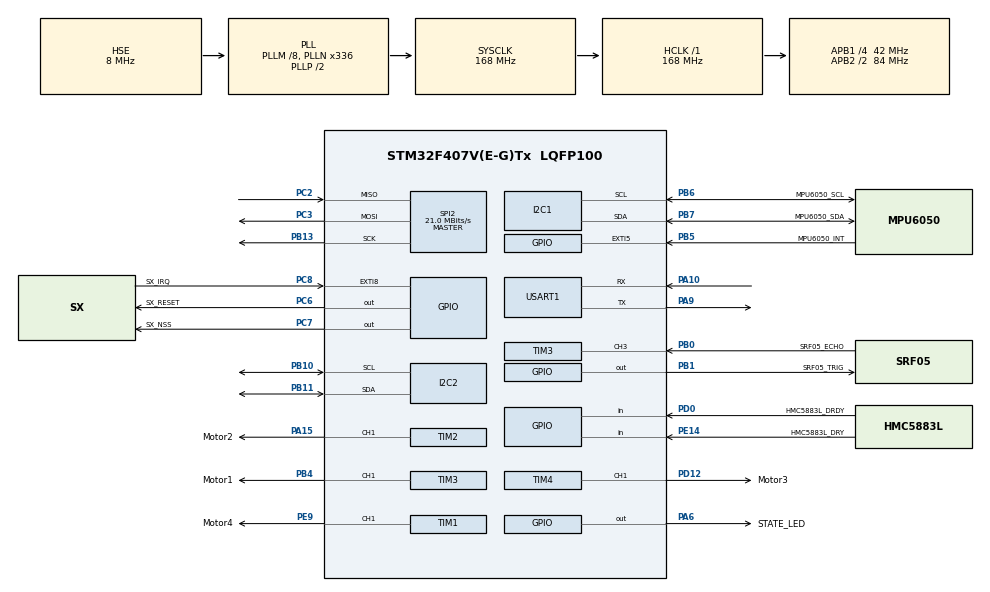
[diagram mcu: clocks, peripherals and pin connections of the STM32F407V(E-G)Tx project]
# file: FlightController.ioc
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Mcu.Family=STM32F4
Mcu.Name=STM32F407V(E-G)Tx
Mcu.Package=LQFP100
NVIC.EXTI9_5_IRQn=true\:0\:0\:false\:false\:true\:true\:true\:true
NVIC.PriorityGroup=NVIC_PRIORITYGROUP_4
NVIC.TIM3_IRQn=true\:0\:0\:false\:false\:true\:true\:true\:true
NVIC.USART1_IRQn=true\:0\:0\:false\:false\:true\:true\:true\:true
PA10.GPIO_PuPd=GPIO_PULLUP
PA10.Mode=Asynchronous
PA10.Signal=USART1_RX
PA13.Mode=Serial_Wire
PA13.Signal=SYS_JTMS-SWDIO
PA14.Mode=Serial_Wire
PA14.Signal=SYS_JTCK-SWCLK
PA15.GPIO_Label=Motor2
PA15.Signal=S_TIM2_CH1_ETR
PA6.GPIO_Label=STATE_LED
PA6.GPIO_PuPd=GPIO_NOPULL
PA6.PinState=GPIO_PIN_SET
PA6.Signal=GPIO_Output
PA9.Mode=Asynchronous
PA9.Signal=USART1_TX
PB0.GPIO_Label=SRF05_ECHO
PB0.Signal=S_TIM3_CH3
PB1.GPIO_Label=SRF05_TRIG
PB1.Signal=GPIO_Output
PB10.Mode=I2C
PB10.Signal=I2C2_SCL
PB11.Mode=I2C
PB11.Signal=I2C2_SDA
PB13.GPIO_Mode=GPIO_MODE_AF_PP
PB13.GPIO_PuPd=GPIO_NOPULL
PB13.GPIO_Speed=GPIO_SPEED_FREQ_VERY_HIGH
PB13.Mode=Full_Duplex_Master
PB13.Signal=SPI2_SCK
PB4.GPIO_Label=Motor1
PB4.Signal=S_TIM3_CH1
PB5.GPIO_Label=MPU6050_INT
PB5.Signal=GPXTI5
PB6.GPIO_Label=MPU6050_SCL
PB6.Mode=I2C
PB6.Signal=I2C1_SCL
PB7.GPIO_Label=MPU6050_SDA
PB7.Mode=I2C
PB7.Signal=I2C1_SDA
PC2.GPIO_Mode=GPIO_MODE_AF_PP
PC2.GPIO_PuPd=GPIO_NOPULL
PC2.GPIO_Speed=GPIO_SPEED_FREQ_VERY_HIGH
PC2.Mode=Full_Duplex_Master
PC2.Signal=SPI2_MISO
PC3.GPIO_Mode=GPIO_MODE_AF_PP
PC3.GPIO_PuPd=GPIO_NOPULL
PC3.GPIO_Speed=GPIO_SPEED_FREQ_VERY_HIGH
PC3.Mode=Full_Duplex_Master
PC3.Signal=SPI2_MOSI
PC6.GPIO_Label=SX_RESET
PC6.PinState=GPIO_PIN_RESET
PC6.Signal=GPIO_Output
PC7.GPIO_Label=SX_NSS
PC7.PinState=GPIO_PIN_SET
PC7.Signal=GPIO_Output
PC8.GPIO_Label=SX_IRQ
PC8.Signal=GPXTI8
PD0.GPIO_Label=HMC5883L_DRDY
PD0.Signal=GPIO_Input
PD12.GPIO_Label=Motor3
PD12.Signal=S_TIM4_CH1
PE14.GPIO_Label=HMC5883L_DRY
PE14.Signal=GPIO_Input
PE9.GPIO_Label=Motor4
PE9.Signal=S_TIM1_CH1
PH0-OSC_IN.Mode=HSE-External-Oscillator
PH0-OSC_IN.Signal=RCC_OSC_IN
PH1-OSC_OUT.Mode=HSE-External-Oscillator
PH1-OSC_OUT.Signal=RCC_OSC_OUT
ProjectManager.HeapSize=0x200
ProjectManager.StackSize=0x400
ProjectManager.TargetToolchain=CMake
RCC.48MHZClocksFreq_Value=84000000
RCC.AHBFreq_Value=168000000
RCC.APB1CLKDivider=RCC_HCLK_DIV4
RCC.APB1Freq_Value=42000000
RCC.APB1TimFreq_Value=84000000
RCC.APB2CLKDivider=RCC_HCLK_DIV2
RCC.APB2Freq_Value=84000000
RCC.APB2TimFreq_Value=168000000
RCC.CortexFreq_Value=168000000
RCC.HCLKFreq_Value=168000000
RCC.HSE_VALUE=8000000
RCC.HSI_VALUE=16000000
RCC.LSE_VALUE=32768
RCC.PLLM=8
RCC.PLLN=336
RCC.PLLSourceVirtual=RCC_PLLSOURCE_HSE
RCC.SYSCLKFreq_VALUE=168000000
RCC.SYSCLKSource=RCC_SYSCLKSOURCE_PLLCLK
RCC.VCOOutputFreq_Value=336000000
SH.S_TIM1_CH1.0=TIM1_CH1,PWM Generation1 CH1
SH.S_TIM2_CH1_ETR.0=TIM2_CH1,PWM Generation1 CH1
SH.S_TIM3_CH1.0=TIM3_CH1,PWM Generation1 CH1
SH.S_TIM3_CH3.0=TIM3_CH3,Input_Capture3_from_TI3
SH.S_TIM4_CH1.0=TIM4_CH1,PWM Generation1 CH1
SPI2.BaudRatePrescaler=SPI_BAUDRATEPRESCALER_2
SPI2.CalculateBaudRate=21.0 MBits/s
SPI2.Direction=SPI_DIRECTION_2LINES
SPI2.Mode=SPI_MODE_MASTER
SPI2.VirtualType=VM_MASTER
TIM1.Channel-PWM\ Generation1\ CH1=TIM_CHANNEL_1
TIM1.Period=19999
TIM1.Prescaler=167
TIM2.Channel-PWM\ Generation1\ CH1=TIM_CHANNEL_1
TIM2.Period=19999
TIM2.Prescaler=83
TIM3.Channel-Input_Capture3_from_TI3=TIM_CHANNEL_3
TIM3.Channel-PWM\ Generation1\ CH1=TIM_CHANNEL_1
TIM3.ICFilter_CH3=15
TIM3.ICPolarity_CH3=TIM_INPUTCHANNELPOLARITY_RISING
TIM3.Period=19999
TIM3.Prescaler=83
TIM4.Channel-PWM\ Generation1\ CH1=TIM_CHANNEL_1
TIM4.Period=19999
TIM4.Prescaler=83
USART1.VirtualMode=VM_ASYNC
board=custom

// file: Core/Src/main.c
/* USER CODE BEGIN Header */
/**
 ******************************************************************************
 * @file           : main.c
 * @brief          : Main program body
 ******************************************************************************
 * @attention
 *
 * Copyright (c) 2025 STMicroelectronics.
 * All rights reserved.
 *
 * This software is licensed under terms that can be found in the LICENSE file
 * in the root directory of this software component.
 * If no LICENSE file comes with this software, it is provided AS-IS.
 *
 ******************************************************************************
 */
/* USER CODE END Header */
#include "main.h"

/* USER CODE BEGIN Includes */
#include "Core.h"
/* USER CODE END Includes */

I2C_HandleTypeDef hi2c1;
I2C_HandleTypeDef hi2c2;

SPI_HandleTypeDef hspi2;

TIM_HandleTypeDef htim1;
TIM_HandleTypeDef htim2;
TIM_HandleTypeDef htim3;
TIM_HandleTypeDef htim4;

UART_HandleTypeDef huart1;

void SystemClock_Config(void);
static void MX_GPIO_Init(void);
static void MX_SPI2_Init(void);
static void MX_TIM1_Init(void);
static void MX_USART1_UART_Init(void);
static void MX_TIM2_Init(void);
static void MX_TIM3_Init(void);
static void MX_TIM4_Init(void);
static void MX_I2C1_Init(void);
static void MX_I2C2_Init(void);

int main(void)
{

  /* MCU Configuration--------------------------------------------------------*/

  /* Reset of all peripherals, Initializes the Flash interface and the Systick. */
  HAL_Init();

  /* Configure the system clock */
  SystemClock_Config();

  /* Initialize all configured peripherals */
  MX_GPIO_Init();
  MX_SPI2_Init();
  MX_TIM1_Init();
  MX_USART1_UART_Init();
  MX_TIM2_Init();
  MX_TIM3_Init();
  MX_TIM4_Init();
  MX_I2C1_Init();
  MX_I2C2_Init();

  /* Infinite loop */
  /* USER CODE BEGIN WHILE */
  Core_init();

  while (1)
  {
    Core_loop();

    /* USER CODE END WHILE */

  }
}

void SystemClock_Config(void)
{
  RCC_OscInitTypeDef RCC_OscInitStruct = {0};
  RCC_ClkInitTypeDef RCC_ClkInitStruct = {0};

  /** Configure the main internal regulator output voltage
  */
  __HAL_RCC_PWR_CLK_ENABLE();
  __HAL_PWR_VOLTAGESCALING_CONFIG(PWR_REGULATOR_VOLTAGE_SCALE1);

  /** Initializes the RCC Oscillators according to the specified parameters
  * in the RCC_OscInitTypeDef structure.
  */
  RCC_OscInitStruct.OscillatorType = RCC_OSCILLATORTYPE_HSE;
  RCC_OscInitStruct.HSEState = RCC_HSE_ON;
  RCC_OscInitStruct.PLL.PLLState = RCC_PLL_ON;
  RCC_OscInitStruct.PLL.PLLSource = RCC_PLLSOURCE_HSE;
  RCC_OscInitStruct.PLL.PLLM = 8;
  RCC_OscInitStruct.PLL.PLLN = 336;
  RCC_OscInitStruct.PLL.PLLP = RCC_PLLP_DIV2;
  RCC_OscInitStruct.PLL.PLLQ = 4;
  if (HAL_RCC_OscConfig(&RCC_OscInitStruct) != HAL_OK)
  {
    Error_Handler();
  }

  /** Initializes the CPU, AHB and APB buses clocks
  */
  RCC_ClkInitStruct.ClockType = RCC_CLOCKTYPE_HCLK|RCC_CLOCKTYPE_SYSCLK
                              |RCC_CLOCKTYPE_PCLK1|RCC_CLOCKTYPE_PCLK2;
  RCC_ClkInitStruct.SYSCLKSource = RCC_SYSCLKSOURCE_PLLCLK;
  RCC_ClkInitStruct.AHBCLKDivider = RCC_SYSCLK_DIV1;
  RCC_ClkInitStruct.APB1CLKDivider = RCC_HCLK_DIV4;
  RCC_ClkInitStruct.APB2CLKDivider = RCC_HCLK_DIV2;

  if (HAL_RCC_ClockConfig(&RCC_ClkInitStruct, FLASH_LATENCY_5) != HAL_OK)
  {
    Error_Handler();
  }
}

static void MX_I2C1_Init(void)
{

  hi2c1.Instance = I2C1;
  hi2c1.Init.ClockSpeed = 100000;
  hi2c1.Init.DutyCycle = I2C_DUTYCYCLE_2;
  hi2c1.Init.OwnAddress1 = 0;
  hi2c1.Init.AddressingMode = I2C_ADDRESSINGMODE_7BIT;
  hi2c1.Init.DualAddressMode = I2C_DUALADDRESS_DISABLE;
  hi2c1.Init.OwnAddress2 = 0;
  hi2c1.Init.GeneralCallMode = I2C_GENERALCALL_DISABLE;
  hi2c1.Init.NoStretchMode = I2C_NOSTRETCH_DISABLE;
  if (HAL_I2C_Init(&hi2c1) != HAL_OK)
  {
    Error_Handler();
  }

}

static void MX_I2C2_Init(void)
{

  hi2c2.Instance = I2C2;
  hi2c2.Init.ClockSpeed = 100000;
  hi2c2.Init.DutyCycle = I2C_DUTYCYCLE_2;
  hi2c2.Init.OwnAddress1 = 0;
  hi2c2.Init.AddressingMode = I2C_ADDRESSINGMODE_7BIT;
  hi2c2.Init.DualAddressMode = I2C_DUALADDRESS_DISABLE;
  hi2c2.Init.OwnAddress2 = 0;
  hi2c2.Init.GeneralCallMode = I2C_GENERALCALL_DISABLE;
  hi2c2.Init.NoStretchMode = I2C_NOSTRETCH_DISABLE;
  if (HAL_I2C_Init(&hi2c2) != HAL_OK)
  {
    Error_Handler();
  }

}

static void MX_SPI2_Init(void)
{

  /* SPI2 parameter configuration*/
  hspi2.Instance = SPI2;
  hspi2.Init.Mode = SPI_MODE_MASTER;
  hspi2.Init.Direction = SPI_DIRECTION_2LINES;
  hspi2.Init.DataSize = SPI_DATASIZE_8BIT;
  hspi2.Init.CLKPolarity = SPI_POLARITY_LOW;
  hspi2.Init.CLKPhase = SPI_PHASE_1EDGE;
  hspi2.Init.NSS = SPI_NSS_SOFT;
  hspi2.Init.BaudRatePrescaler = SPI_BAUDRATEPRESCALER_2;
  hspi2.Init.FirstBit = SPI_FIRSTBIT_MSB;
  hspi2.Init.TIMode = SPI_TIMODE_DISABLE;
  hspi2.Init.CRCCalculation = SPI_CRCCALCULATION_DISABLE;
  hspi2.Init.CRCPolynomial = 10;
  if (HAL_SPI_Init(&hspi2) != HAL_OK)
  {
    Error_Handler();
  }

}

static void MX_TIM1_Init(void)
{

  TIM_MasterConfigTypeDef sMasterConfig = {0};
  TIM_OC_InitTypeDef sConfigOC = {0};
  TIM_BreakDeadTimeConfigTypeDef sBreakDeadTimeConfig = {0};

  htim1.Instance = TIM1;
  htim1.Init.Prescaler = 167;
  htim1.Init.CounterMode = TIM_COUNTERMODE_UP;
  htim1.Init.Period = 19999;
  htim1.Init.ClockDivision = TIM_CLOCKDIVISION_DIV1;
  htim1.Init.RepetitionCounter = 0;
  htim1.Init.AutoReloadPreload = TIM_AUTORELOAD_PRELOAD_DISABLE;
  if (HAL_TIM_PWM_Init(&htim1) != HAL_OK)
  {
    Error_Handler();
  }
  sMasterConfig.MasterOutputTrigger = TIM_TRGO_RESET;
  sMasterConfig.MasterSlaveMode = TIM_MASTERSLAVEMODE_DISABLE;
  if (HAL_TIMEx_MasterConfigSynchronization(&htim1, &sMasterConfig) != HAL_OK)
  {
    Error_Handler();
  }
  sConfigOC.OCMode = TIM_OCMODE_PWM1;
  sConfigOC.Pulse = 0;
  sConfigOC.OCPolarity = TIM_OCPOLARITY_HIGH;
  sConfigOC.OCNPolarity = TIM_OCNPOLARITY_HIGH;
  sConfigOC.OCFastMode = TIM_OCFAST_DISABLE;
  sConfigOC.OCIdleState = TIM_OCIDLESTATE_RESET;
  sConfigOC.OCNIdleState = TIM_OCNIDLESTATE_RESET;
  if (HAL_TIM_PWM_ConfigChannel(&htim1, &sConfigOC, TIM_CHANNEL_1) != HAL_OK)
  {
    Error_Handler();
  }
  sBreakDeadTimeConfig.OffStateRunMode = TIM_OSSR_DISABLE;
  sBreakDeadTimeConfig.OffStateIDLEMode = TIM_OSSI_DISABLE;
  sBreakDeadTimeConfig.LockLevel = TIM_LOCKLEVEL_OFF;
  sBreakDeadTimeConfig.DeadTime = 0;
  sBreakDeadTimeConfig.BreakState = TIM_BREAK_DISABLE;
  sBreakDeadTimeConfig.BreakPolarity = TIM_BREAKPOLARITY_HIGH;
  sBreakDeadTimeConfig.AutomaticOutput = TIM_AUTOMATICOUTPUT_DISABLE;
  if (HAL_TIMEx_ConfigBreakDeadTime(&htim1, &sBreakDeadTimeConfig) != HAL_OK)
  {
    Error_Handler();
  }
  HAL_TIM_MspPostInit(&htim1);

}

static void MX_TIM2_Init(void)
{

  TIM_MasterConfigTypeDef sMasterConfig = {0};
  TIM_OC_InitTypeDef sConfigOC = {0};

  htim2.Instance = TIM2;
  htim2.Init.Prescaler = 83;
  htim2.Init.CounterMode = TIM_COUNTERMODE_UP;
  htim2.Init.Period = 19999;
  htim2.Init.ClockDivision = TIM_CLOCKDIVISION_DIV1;
  htim2.Init.AutoReloadPreload = TIM_AUTORELOAD_PRELOAD_DISABLE;
  if (HAL_TIM_PWM_Init(&htim2) != HAL_OK)
  {
    Error_Handler();
  }
  sMasterConfig.MasterOutputTrigger = TIM_TRGO_RESET;
  sMasterConfig.MasterSlaveMode = TIM_MASTERSLAVEMODE_DISABLE;
  if (HAL_TIMEx_MasterConfigSynchronization(&htim2, &sMasterConfig) != HAL_OK)
  {
    Error_Handler();
  }
  sConfigOC.OCMode = TIM_OCMODE_PWM1;
  sConfigOC.Pulse = 0;
  sConfigOC.OCPolarity = TIM_OCPOLARITY_HIGH;
  sConfigOC.OCFastMode = TIM_OCFAST_DISABLE;
  if (HAL_TIM_PWM_ConfigChannel(&htim2, &sConfigOC, TIM_CHANNEL_1) != HAL_OK)
  {
    Error_Handler();
  }
  HAL_TIM_MspPostInit(&htim2);

}

static void MX_TIM3_Init(void)
{

  TIM_MasterConfigTypeDef sMasterConfig = {0};
  TIM_OC_InitTypeDef sConfigOC = {0};
  TIM_IC_InitTypeDef sConfigIC = {0};

  htim3.Instance = TIM3;
  htim3.Init.Prescaler = 83;
  htim3.Init.CounterMode = TIM_COUNTERMODE_UP;
  htim3.Init.Period = 19999;
  htim3.Init.ClockDivision = TIM_CLOCKDIVISION_DIV1;
  htim3.Init.AutoReloadPreload = TIM_AUTORELOAD_PRELOAD_DISABLE;
  if (HAL_TIM_PWM_Init(&htim3) != HAL_OK)
  {
    Error_Handler();
  }
  if (HAL_TIM_IC_Init(&htim3) != HAL_OK)
  {
    Error_Handler();
  }
  sMasterConfig.MasterOutputTrigger = TIM_TRGO_RESET;
  sMasterConfig.MasterSlaveMode = TIM_MASTERSLAVEMODE_DISABLE;
  if (HAL_TIMEx_MasterConfigSynchronization(&htim3, &sMasterConfig) != HAL_OK)
  {
    Error_Handler();
  }
  sConfigOC.OCMode = TIM_OCMODE_PWM1;
  sConfigOC.Pulse = 0;
  sConfigOC.OCPolarity = TIM_OCPOLARITY_HIGH;
  sConfigOC.OCFastMode = TIM_OCFAST_DISABLE;
  if (HAL_TIM_PWM_ConfigChannel(&htim3, &sConfigOC, TIM_CHANNEL_1) != HAL_OK)
  {
    Error_Handler();
  }
  sConfigIC.ICPolarity = TIM_INPUTCHANNELPOLARITY_RISING;
  sConfigIC.ICSelection = TIM_ICSELECTION_DIRECTTI;
  sConfigIC.ICPrescaler = TIM_ICPSC_DIV1;
  sConfigIC.ICFilter = 15;
  if (HAL_TIM_IC_ConfigChannel(&htim3, &sConfigIC, TIM_CHANNEL_3) != HAL_OK)
  {
    Error_Handler();
  }
  HAL_TIM_MspPostInit(&htim3);

}

static void MX_TIM4_Init(void)
{

  TIM_MasterConfigTypeDef sMasterConfig = {0};
  TIM_OC_InitTypeDef sConfigOC = {0};

  htim4.Instance = TIM4;
  htim4.Init.Prescaler = 83;
  htim4.Init.CounterMode = TIM_COUNTERMODE_UP;
  htim4.Init.Period = 19999;
  htim4.Init.ClockDivision = TIM_CLOCKDIVISION_DIV1;
  htim4.Init.AutoReloadPreload = TIM_AUTORELOAD_PRELOAD_DISABLE;
  if (HAL_TIM_PWM_Init(&htim4) != HAL_OK)
  {
    Error_Handler();
  }
  sMasterConfig.MasterOutputTrigger = TIM_TRGO_RESET;
  sMasterConfig.MasterSlaveMode = TIM_MASTERSLAVEMODE_DISABLE;
  if (HAL_TIMEx_MasterConfigSynchronization(&htim4, &sMasterConfig) != HAL_OK)
  {
    Error_Handler();
  }
  sConfigOC.OCMode = TIM_OCMODE_PWM1;
  sConfigOC.Pulse = 0;
  sConfigOC.OCPolarity = TIM_OCPOLARITY_HIGH;
  sConfigOC.OCFastMode = TIM_OCFAST_DISABLE;
  if (HAL_TIM_PWM_ConfigChannel(&htim4, &sConfigOC, TIM_CHANNEL_1) != HAL_OK)
  {
    Error_Handler();
  }
  HAL_TIM_MspPostInit(&htim4);

}

static void MX_USART1_UART_Init(void)
{

  huart1.Instance = USART1;
  huart1.Init.BaudRate = 115200;
  huart1.Init.WordLength = UART_WORDLENGTH_8B;
  huart1.Init.StopBits = UART_STOPBITS_1;
  huart1.Init.Parity = UART_PARITY_NONE;
  huart1.Init.Mode = UART_MODE_TX_RX;
  huart1.Init.HwFlowCtl = UART_HWCONTROL_NONE;
  huart1.Init.OverSampling = UART_OVERSAMPLING_16;
  if (HAL_UART_Init(&huart1) != HAL_OK)
  {
    Error_Handler();
  }

}

static void MX_GPIO_Init(void)
{
  GPIO_InitTypeDef GPIO_InitStruct = {0};

  /* GPIO Ports Clock Enable */
  __HAL_RCC_GPIOH_CLK_ENABLE();
  __HAL_RCC_GPIOC_CLK_ENABLE();
  __HAL_RCC_GPIOA_CLK_ENABLE();
  __HAL_RCC_GPIOB_CLK_ENABLE();
  __HAL_RCC_GPIOE_CLK_ENABLE();
  __HAL_RCC_GPIOD_CLK_ENABLE();

  /*Configure GPIO pin Output Level */
  HAL_GPIO_WritePin(STATE_LED_GPIO_Port, STATE_LED_Pin, GPIO_PIN_SET);

  /*Configure GPIO pin Output Level */
  HAL_GPIO_WritePin(SRF05_TRIG_GPIO_Port, SRF05_TRIG_Pin, GPIO_PIN_RESET);

  /*Configure GPIO pin Output Level */
  HAL_GPIO_WritePin(SX_RESET_GPIO_Port, SX_RESET_Pin, GPIO_PIN_RESET);

  /*Configure GPIO pin Output Level */
  HAL_GPIO_WritePin(SX_NSS_GPIO_Port, SX_NSS_Pin, GPIO_PIN_SET);

  /*Configure GPIO pin : STATE_LED_Pin */
  GPIO_InitStruct.Pin = STATE_LED_Pin;
  GPIO_InitStruct.Mode = GPIO_MODE_OUTPUT_PP;
  GPIO_InitStruct.Pull = GPIO_NOPULL;
  GPIO_InitStruct.Speed = GPIO_SPEED_FREQ_LOW;
  HAL_GPIO_Init(STATE_LED_GPIO_Port, &GPIO_InitStruct);

  /*Configure GPIO pin : SRF05_TRIG_Pin */
  GPIO_InitStruct.Pin = SRF05_TRIG_Pin;
  GPIO_InitStruct.Mode = GPIO_MODE_OUTPUT_PP;
  GPIO_InitStruct.Pull = GPIO_NOPULL;
  GPIO_InitStruct.Speed = GPIO_SPEED_FREQ_LOW;
  HAL_GPIO_Init(SRF05_TRIG_GPIO_Port, &GPIO_InitStruct);

  /*Configure GPIO pin : HMC5883L_DRY_Pin */
  GPIO_InitStruct.Pin = HMC5883L_DRY_Pin;
  GPIO_InitStruct.Mode = GPIO_MODE_INPUT;
  GPIO_InitStruct.Pull = GPIO_NOPULL;
  HAL_GPIO_Init(HMC5883L_DRY_GPIO_Port, &GPIO_InitStruct);

  /*Configure GPIO pins : SX_RESET_Pin SX_NSS_Pin */
  GPIO_InitStruct.Pin = SX_RESET_Pin|SX_NSS_Pin;
  GPIO_InitStruct.Mode = GPIO_MODE_OUTPUT_PP;
  GPIO_InitStruct.Pull = GPIO_NOPULL;
  GPIO_InitStruct.Speed = GPIO_SPEED_FREQ_LOW;
  HAL_GPIO_Init(GPIOC, &GPIO_InitStruct);

  /*Configure GPIO pin : SX_IRQ_Pin */
  GPIO_InitStruct.Pin = SX_IRQ_Pin;
  GPIO_InitStruct.Mode = GPIO_MODE_IT_RISING;
  GPIO_InitStruct.Pull = GPIO_NOPULL;
  HAL_GPIO_Init(SX_IRQ_GPIO_Port, &GPIO_InitStruct);

  /*Configure GPIO pin : HMC5883L_DRDY_Pin */
  GPIO_InitStruct.Pin = HMC5883L_DRDY_Pin;
  GPIO_InitStruct.Mode = GPIO_MODE_INPUT;
  GPIO_InitStruct.Pull = GPIO_NOPULL;
  HAL_GPIO_Init(HMC5883L_DRDY_GPIO_Port, &GPIO_InitStruct);

  /*Configure GPIO pin : MPU6050_INT_Pin */
  GPIO_InitStruct.Pin = MPU6050_INT_Pin;
  GPIO_InitStruct.Mode = GPIO_MODE_IT_RISING;
  GPIO_InitStruct.Pull = GPIO_NOPULL;
  HAL_GPIO_Init(MPU6050_INT_GPIO_Port, &GPIO_InitStruct);

  /* EXTI interrupt init*/
  HAL_NVIC_SetPriority(EXTI9_5_IRQn, 0, 0);
  HAL_NVIC_EnableIRQ(EXTI9_5_IRQn);

}

/* USER CODE BEGIN 4 */
// void HAL_TIM_IC_CaptureCallback(TIM_HandleTypeDef *htim)
// {

//     HAL_TIM_ReadCapturedValue(&htim2, TIM_CHANNEL_4);

// }
/* USER CODE END 4 */

void Error_Handler(void)
{
  __disable_irq();
  while (1)
  {
  }
}
